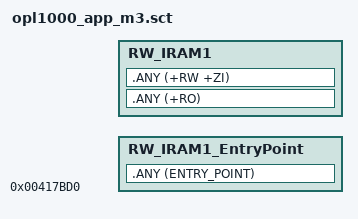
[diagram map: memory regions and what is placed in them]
#! armcc -E

#define SCT_PATCH_START 0x00417BD0
#define SCT_PATCH_LEN   0x00440000 - SCT_PATCH_START
#define SHM_PATCH_START 0x80000000
#define SHM_PATCH_LEN   0x00007AF0

LR_IROM1 SCT_PATCH_START SCT_PATCH_LEN
{
    RW_IRAM1_EntryPoint +0
    {
        .ANY (ENTRY_POINT)
    }
    RW_IRAM1 +0 
    {
       .ANY (+RO)
       .ANY (+RW +ZI)
    }
}
ScatterAssert(ImageLength(LR_IROM1) <= SCT_PATCH_LEN)


;LR_IROM2 SHM_PATCH_START SHM_PATCH_LEN
;{
;    RW_IRAM2_ShareRam + 0 SHM_PATCH_LEN
;    {
;        .ANY (SHM_REGION)
;    }
;}
;ScatterAssert(ImageLength(LR_IROM2) <= SHM_PATCH_LEN)
